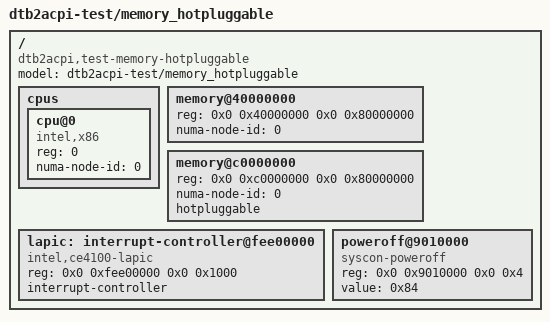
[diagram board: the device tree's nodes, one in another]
/dts-v1/;

/* Two memory regions:
 *   memory@40000000 — `status = "okay"` (implicit), no `hotpluggable`
 *                     → SRAT Memory Affinity flags = ENABLED (0x1)
 *   memory@c0000000 — `status = "okay"` (implicit), `hotpluggable`
 *                     present → flags = ENABLED | HOT_PLUGGABLE (0x3)
 *
 * Per DT spec §3.4 Table 3.3, `hotpluggable` is a standard memory-node
 * property of value type <empty> — its presence alone is the hint.
 */

/ {
	#address-cells = <2>;
	#size-cells = <2>;
	model = "dtb2acpi-test/memory_hotpluggable";
	compatible = "dtb2acpi,test-memory-hotpluggable";

	cpus {
		#address-cells = <1>;
		#size-cells = <0>;

		cpu@0 {
			device_type = "cpu";
			reg = <0>;
			compatible = "intel,x86";
			numa-node-id = <0>;
		};
	};

	memory@40000000 {
		device_type = "memory";
		reg = <0x0 0x40000000 0x0 0x80000000>;
		numa-node-id = <0>;
	};

	memory@c0000000 {
		device_type = "memory";
		reg = <0x0 0xc0000000 0x0 0x80000000>;
		numa-node-id = <0>;
		hotpluggable;
	};

		lapic: interrupt-controller@fee00000 {
		compatible = "intel,ce4100-lapic";
		reg = <0x0 0xfee00000 0x0 0x1000>;
		interrupt-controller;
		#interrupt-cells = <2>;
	};
		poweroff@9010000 {
		compatible = "syscon-poweroff";
		reg = <0x0 0x9010000 0x0 0x4>;
		value = <0x84>;
	};
};
